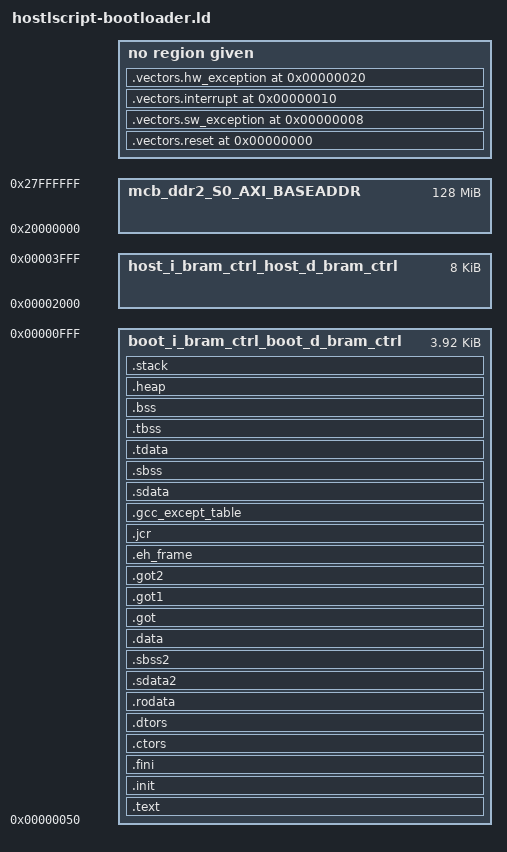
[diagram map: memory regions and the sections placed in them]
/*******************************************************************/
/*                                                                 */
/* This file is automatically generated by linker script generator.*/
/*                                                                 */
/* Version: Xilinx EDK 14.7 EDK_P.20131013                         */
/*                                                                 */
/* Copyright (c) 2010 Xilinx, Inc.  All rights reserved.           */
/*                                                                 */
/* Description : MicroBlaze Linker Script                          */
/*                                                                 */
/*******************************************************************/

_STACK_SIZE = DEFINED(_STACK_SIZE) ? _STACK_SIZE : 0x0;
_HEAP_SIZE = DEFINED(_HEAP_SIZE) ? _HEAP_SIZE : 0x30;

/* Define Memories in the system */

MEMORY
{
    host_i_bram_ctrl_host_d_bram_ctrl : ORIGIN = 0x00002000, LENGTH = 0x00002000
    boot_i_bram_ctrl_boot_d_bram_ctrl : ORIGIN = 0x00000050, LENGTH = 0x00000FB0
    mcb_ddr2_S0_AXI_BASEADDR : ORIGIN = 0x20000000, LENGTH = 0x08000000
}

/* Specify the default entry point to the program */

ENTRY(_start)

/* Define the sections, and where they are mapped in memory */

SECTIONS
{
    .vectors.reset 0x00000000 : {
        KEEP(*(.vectors.reset))
    }

    .vectors.sw_exception 0x00000008 : {
        KEEP(*(.vectors.sw_exception))
    }

    .vectors.interrupt 0x00000010 : {
        KEEP(*(.vectors.interrupt))
    }

    .vectors.hw_exception 0x00000020 : {
        KEEP(*(.vectors.hw_exception))
    }

    .text               : {
        *(.text)
        *(.text.*)
        *(.gnu.linkonce.t.*)
    } > boot_i_bram_ctrl_boot_d_bram_ctrl

    .init               : {
        KEEP(*(.init))
    } > boot_i_bram_ctrl_boot_d_bram_ctrl

    .fini               : {
        KEEP(*(.fini))
    } > boot_i_bram_ctrl_boot_d_bram_ctrl

    .ctors              : {
        __CTOR_LIST__ = .;
        ___CTORS_LIST___ = .;
        KEEP(*crtbegin.o(.ctors))
        KEEP(*(EXCLUDE_FILE(*crtend.o).ctors))
        KEEP(*(SORT(.ctors.*)))
        KEEP(*(.ctors))
        __CTOR_END__ = .;
        ___CTORS_END___ = .;
    } > boot_i_bram_ctrl_boot_d_bram_ctrl

    .dtors              : {
        __DTOR_LIST__ = .;
        ___DTORS_LIST___ = .;
        KEEP(*crtbegin.o(.dtors))
        KEEP(*(EXCLUDE_FILE(*crtend.o).dtors))
        KEEP(*(SORT(.dtors.*)))
        KEEP(*(.dtors))
        PROVIDE(__DTOR_END__ = .);
        PROVIDE(___DTORS_END___ = .);
    } > boot_i_bram_ctrl_boot_d_bram_ctrl

    .rodata             : {
        __rodata_start = .;
        *(.rodata)
        *(.rodata.*)
        *(.gnu.linkonce.r.*)
        __rodata_end = .;
    } > boot_i_bram_ctrl_boot_d_bram_ctrl

    .sdata2             : {
        . = ALIGN(8);
        __sdata2_start = .;
        *(.sdata2)
        *(.sdata2.*)
        *(.gnu.linkonce.s2.*)
        . = ALIGN(8);
        __sdata2_end = .;
    } > boot_i_bram_ctrl_boot_d_bram_ctrl

    .sbss2              : {
        __sbss2_start = .;
        *(.sbss2)
        *(.sbss2.*)
        *(.gnu.linkonce.sb2.*)
        __sbss2_end = .;
    } > boot_i_bram_ctrl_boot_d_bram_ctrl

    .data               : {
        . = ALIGN(4);
        __data_start = .;
        *(.data)
        *(.data.*)
        *(.gnu.linkonce.d.*)
        __data_end = .;
    } > boot_i_bram_ctrl_boot_d_bram_ctrl

    .got                : {
        *(.got)
    } > boot_i_bram_ctrl_boot_d_bram_ctrl

    .got1               : {
        *(.got1)
    } > boot_i_bram_ctrl_boot_d_bram_ctrl

    .got2               : {
        *(.got2)
    } > boot_i_bram_ctrl_boot_d_bram_ctrl

    .eh_frame           : {
        *(.eh_frame)
    } > boot_i_bram_ctrl_boot_d_bram_ctrl

    .jcr                : {
        *(.jcr)
    } > boot_i_bram_ctrl_boot_d_bram_ctrl

    .gcc_except_table   : {
        *(.gcc_except_table)
    } > boot_i_bram_ctrl_boot_d_bram_ctrl

    .sdata              : {
        . = ALIGN(8);
        __sdata_start = .;
        *(.sdata)
        *(.sdata.*)
        *(.gnu.linkonce.s.*)
        __sdata_end = .;
    } > boot_i_bram_ctrl_boot_d_bram_ctrl

    .sbss(NOLOAD) : {
        . = ALIGN(4);
        __sbss_start = .;
        *(.sbss)
        *(.sbss.*)
        *(.gnu.linkonce.sb.*)
        . = ALIGN(8);
        __sbss_end = .;
    } > boot_i_bram_ctrl_boot_d_bram_ctrl

    .tdata  : {
        __tdata_start = .;
        *(.tdata)
        *(.tdata.*)
        *(.gnu.linkonce.td.*)
        __tdata_end = .;
    } > boot_i_bram_ctrl_boot_d_bram_ctrl

    .tbss   : {
        __tbss_start = .;
        *(.tbss)
        *(.tbss.*)
        *(.gnu.linkonce.tb.*)
        __tbss_end = .;
    } > boot_i_bram_ctrl_boot_d_bram_ctrl

    .bss(NOLOAD) : {
        . = ALIGN(4);
        __bss_start = .;
        *(.bss)
        *(.bss.*)
        *(.gnu.linkonce.b.*)
        *(COMMON)
        . = ALIGN(4);
        __bss_end = .;
    } > boot_i_bram_ctrl_boot_d_bram_ctrl

    _SDA_BASE_ = __sdata_start + ((__sbss_end - __sdata_start) / 2 );

    _SDA2_BASE_ = __sdata2_start + ((__sbss2_end - __sdata2_start) / 2 );

    /* Generate Stack and Heap definitions */

    .heap(NOLOAD) : {
        . = ALIGN(8);
        _heap = .;
        _heap_start = .;
        . += _HEAP_SIZE;
        _heap_end = .;
    } > boot_i_bram_ctrl_boot_d_bram_ctrl

    .stack(NOLOAD) : {
        _stack_end = .;
        . += _STACK_SIZE;
        . = ALIGN(8);
        _stack = .;
        __stack = _stack;
    } > boot_i_bram_ctrl_boot_d_bram_ctrl

    _end = .;
}
